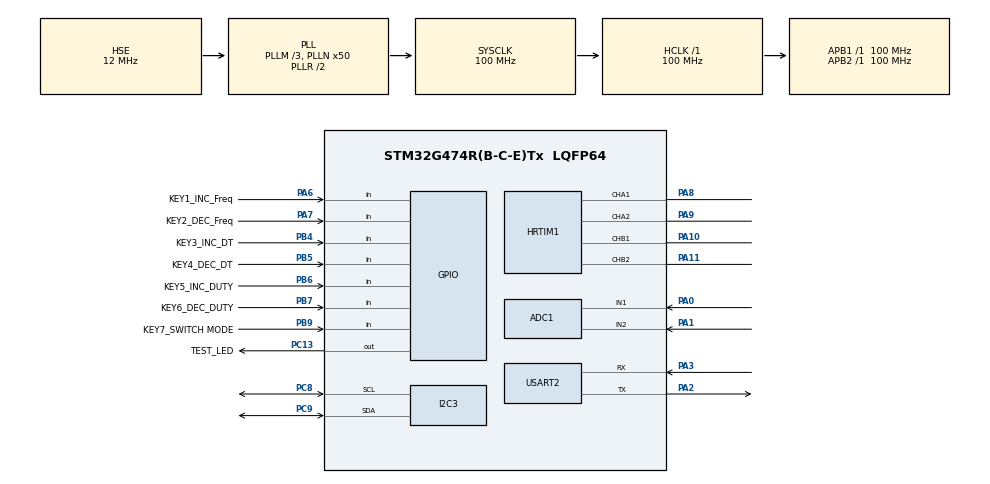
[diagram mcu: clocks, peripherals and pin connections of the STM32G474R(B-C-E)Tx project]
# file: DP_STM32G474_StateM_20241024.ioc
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ADC1.Channel-1\#ChannelRegularConversion=ADC_CHANNEL_1
ADC1.NbrOfConversionFlag=1
ADC1.OffsetNumber-1\#ChannelRegularConversion=ADC_OFFSET_NONE
ADC1.Rank-1\#ChannelRegularConversion=1
ADC1.SamplingTime-1\#ChannelRegularConversion=ADC_SAMPLETIME_2CYCLES_5
ADC1.master=1
Dma.ADC1.2.Direction=DMA_PERIPH_TO_MEMORY
Dma.ADC1.2.EventEnable=DISABLE
Dma.ADC1.2.Instance=DMA1_Channel1
Dma.ADC1.2.MemDataAlignment=DMA_MDATAALIGN_HALFWORD
Dma.ADC1.2.MemInc=DMA_MINC_ENABLE
Dma.ADC1.2.Mode=DMA_NORMAL
Dma.ADC1.2.PeriphDataAlignment=DMA_PDATAALIGN_HALFWORD
Dma.ADC1.2.PeriphInc=DMA_PINC_DISABLE
Dma.ADC1.2.Polarity=HAL_DMAMUX_REQ_GEN_RISING
Dma.ADC1.2.Priority=DMA_PRIORITY_LOW
Dma.ADC1.2.RequestNumber=1
Dma.ADC1.2.SignalID=NONE
Dma.ADC1.2.SyncEnable=DISABLE
Dma.ADC1.2.SyncPolarity=HAL_DMAMUX_SYNC_NO_EVENT
Dma.ADC1.2.SyncRequestNumber=1
Dma.ADC1.2.SyncSignalID=NONE
Dma.I2C3_TX.1.Direction=DMA_MEMORY_TO_PERIPH
Dma.I2C3_TX.1.EventEnable=DISABLE
Dma.I2C3_TX.1.Instance=DMA1_Channel2
Dma.I2C3_TX.1.MemDataAlignment=DMA_MDATAALIGN_BYTE
Dma.I2C3_TX.1.MemInc=DMA_MINC_ENABLE
Dma.I2C3_TX.1.Mode=DMA_NORMAL
Dma.I2C3_TX.1.PeriphDataAlignment=DMA_PDATAALIGN_BYTE
Dma.I2C3_TX.1.PeriphInc=DMA_PINC_DISABLE
Dma.I2C3_TX.1.Polarity=HAL_DMAMUX_REQ_GEN_RISING
Dma.I2C3_TX.1.Priority=DMA_PRIORITY_LOW
Dma.I2C3_TX.1.RequestNumber=1
Dma.I2C3_TX.1.SignalID=NONE
Dma.I2C3_TX.1.SyncEnable=DISABLE
Dma.I2C3_TX.1.SyncPolarity=HAL_DMAMUX_SYNC_NO_EVENT
Dma.I2C3_TX.1.SyncRequestNumber=1
Dma.I2C3_TX.1.SyncSignalID=NONE
Dma.Request0=USART2_TX
Dma.Request1=I2C3_TX
Dma.Request2=ADC1
Dma.USART2_TX.0.Direction=DMA_MEMORY_TO_PERIPH
Dma.USART2_TX.0.EventEnable=DISABLE
Dma.USART2_TX.0.Instance=DMA1_Channel3
Dma.USART2_TX.0.MemDataAlignment=DMA_MDATAALIGN_BYTE
Dma.USART2_TX.0.MemInc=DMA_MINC_ENABLE
Dma.USART2_TX.0.Mode=DMA_NORMAL
Dma.USART2_TX.0.PeriphDataAlignment=DMA_PDATAALIGN_BYTE
Dma.USART2_TX.0.PeriphInc=DMA_PINC_DISABLE
Dma.USART2_TX.0.Polarity=HAL_DMAMUX_REQ_GEN_RISING
Dma.USART2_TX.0.Priority=DMA_PRIORITY_LOW
Dma.USART2_TX.0.RequestNumber=1
Dma.USART2_TX.0.SignalID=NONE
Dma.USART2_TX.0.SyncEnable=DISABLE
Dma.USART2_TX.0.SyncPolarity=HAL_DMAMUX_SYNC_NO_EVENT
Dma.USART2_TX.0.SyncRequestNumber=1
Dma.USART2_TX.0.SyncSignalID=NONE
HRTIM1.CompareUnit1-Output_TA1TA2=HRTIM_COMPAREUNIT_1
HRTIM1.CompareUnit1-Output_TB1TB2=HRTIM_COMPAREUNIT_1
HRTIM1.CompareUnit2-Output_TA1TA2=HRTIM_COMPAREUNIT_2
HRTIM1.CompareUnit2-Output_TB1TB2=HRTIM_COMPAREUNIT_2
HRTIM1.CompareUnit3-Output_TA1TA2=HRTIM_COMPAREUNIT_3
HRTIM1.CompareUnit3-Output_TB1TB2=HRTIM_COMPAREUNIT_3
HRTIM1.CompareValue1-Output_TA1TA2=0
HRTIM1.CompareValue1-Output_TB1TB2=0
HRTIM1.CompareValue2-Output_TA1TA2=16000/2
HRTIM1.CompareValue2-Output_TB1TB2=16000/2
HRTIM1.CompareValue3-Output_TA1TA2=0
HRTIM1.CompareValue3-Output_TB1TB2=0
HRTIM1.Configuration_TA=Waveform
HRTIM1.NumberResetSource1-Output_TA1TA2=1
HRTIM1.NumberResetSource1-Output_TB1TB2=1
HRTIM1.NumberResetSource2_TA=1
HRTIM1.NumberResetSource2_TB=1
HRTIM1.NumberResetTrigger-Output_TA1TA2=1
HRTIM1.NumberResetTrigger-Output_TB1TB2=1
HRTIM1.NumberSetSource1-Output_TA1TA2=1
HRTIM1.NumberSetSource1-Output_TB1TB2=1
HRTIM1.NumberSetSource2_TA=1
HRTIM1.NumberSetSource2_TB=1
HRTIM1.NumberUpdateTrigger-Output_TA1TA2=1
HRTIM1.NumberUpdateTrigger-Output_TB1TB2=1
HRTIM1.Periode_TA=16000
HRTIM1.Periode_TB=16000
HRTIM1.Polarity1-Output_TA1TA2=HRTIM_OUTPUTPOLARITY_LOW
HRTIM1.Polarity2-Output_TA1TA2=HRTIM_OUTPUTPOLARITY_LOW
HRTIM1.PrescalerRatio_TA=HRTIM_PRESCALERRATIO_MUL16
HRTIM1.PrescalerRatio_TB=HRTIM_PRESCALERRATIO_MUL16
HRTIM1.RepetitionCounter-Output_TA1TA2=0
HRTIM1.RepetitionCounter-Output_TB1TB2=0
HRTIM1.ResetOutput1_Source1-Output_TA1TA2=HRTIM_OUTPUTRESET_TIMPER
HRTIM1.ResetOutput1_Source1-Output_TB1TB2=HRTIM_OUTPUTRESET_TIMCMP1
HRTIM1.ResetOutput2_Source1-Output_TA1TA2=HRTIM_OUTPUTRESET_TIMPER
HRTIM1.ResetOutput2_Source1-Output_TB1TB2=HRTIM_OUTPUTRESET_TIMCMP1
HRTIM1.ResetTrigger1-Output_TA1TA2=HRTIM_TIMRESETTRIGGER_UPDATE
HRTIM1.ResetTrigger1-Output_TB1TB2=HRTIM_TIMRESETTRIGGER_UPDATE
HRTIM1.ResetUpdate-Output_TA1TA2=HRTIM_TIMUPDATEONRESET_ENABLED
HRTIM1.ResetUpdate-Output_TB1TB2=HRTIM_TIMUPDATEONRESET_ENABLED
HRTIM1.SetOutput1_Source1-Output_TA1TA2=HRTIM_OUTPUTSET_TIMCMP2
HRTIM1.SetOutput1_Source1-Output_TB1TB2=HRTIM_OUTPUTSET_TIMCMP2
HRTIM1.SetOutput2_Source1-Output_TA1TA2=HRTIM_OUTPUTSET_TIMCMP2
HRTIM1.SetOutput2_Source1-Output_TB1TB2=HRTIM_OUTPUTSET_TIMCMP2
HRTIM1.UpdateTrigger1-Output_TA1TA2=HRTIM_TIMUPDATETRIGGER_TIMER_A
HRTIM1.UpdateTrigger1-Output_TB1TB2=HRTIM_TIMUPDATETRIGGER_TIMER_A
I2C3.Timing=0x20B182BE
Mcu.Family=STM32G4
Mcu.Name=STM32G474R(B-C-E)Tx
Mcu.Package=LQFP64
NVIC.ADC1_2_IRQn=true\:0\:0\:false\:false\:true\:true\:true\:true
NVIC.DMA1_Channel1_IRQn=true\:0\:0\:false\:false\:true\:false\:true\:true
NVIC.DMA1_Channel2_IRQn=true\:0\:0\:false\:false\:true\:false\:true\:true
NVIC.DMA1_Channel3_IRQn=true\:0\:0\:false\:false\:true\:false\:true\:true
NVIC.PriorityGroup=NVIC_PRIORITYGROUP_4
NVIC.TIM2_IRQn=true\:0\:0\:false\:false\:true\:true\:true\:true
NVIC.USART2_IRQn=true\:0\:0\:false\:false\:true\:true\:true\:true
PA0.Mode=IN1-Single-Ended
PA0.Signal=ADC1_IN1
PA1.Mode=IN1-Differential
PA1.Signal=ADC1_IN2
PA10.Mode=Output_TB1TB2
PA10.Signal=HRTIM1_CHB1
PA11.Mode=Output_TB1TB2
PA11.Signal=HRTIM1_CHB2
PA13.Mode=Serial_Wire
PA13.Signal=SYS_JTMS-SWDIO
PA14.Mode=Serial_Wire
PA14.Signal=SYS_JTCK-SWCLK
PA2.Mode=Asynchronous
PA2.Signal=USART2_TX
PA3.Mode=Asynchronous
PA3.Signal=USART2_RX
PA6.GPIO_Label=KEY1_INC_Freq
PA6.GPIO_PuPd=GPIO_PULLUP
PA6.Signal=GPIO_Input
PA7.GPIO_Label=KEY2_DEC_Freq
PA7.GPIO_PuPd=GPIO_PULLUP
PA7.Signal=GPIO_Input
PA8.Mode=Output_TA1TA2
PA8.Signal=HRTIM1_CHA1
PA9.Mode=Output_TA1TA2
PA9.Signal=HRTIM1_CHA2
PB4.GPIO_Label=KEY3_INC_DT
PB4.GPIO_PuPd=GPIO_PULLUP
PB4.Signal=GPIO_Input
PB5.GPIO_Label=KEY4_DEC_DT
PB5.GPIO_PuPd=GPIO_PULLUP
PB5.Signal=GPIO_Input
PB6.GPIO_Label=KEY5_INC_DUTY
PB6.GPIO_PuPd=GPIO_PULLUP
PB6.Signal=GPIO_Input
PB7.GPIO_Label=KEY6_DEC_DUTY
PB7.GPIO_PuPd=GPIO_PULLUP
PB7.Signal=GPIO_Input
PB9.GPIO_Label=KEY7_SWITCH MODE
PB9.GPIO_PuPd=GPIO_PULLUP
PB9.Signal=GPIO_Input
PC13.GPIO_Label=TEST_LED
PC13.PinState=GPIO_PIN_SET
PC13.Signal=GPIO_Output
PC14-OSC32_IN.Mode=LSE-External-Oscillator
PC14-OSC32_IN.Signal=RCC_OSC32_IN
PC15-OSC32_OUT.Mode=LSE-External-Oscillator
PC15-OSC32_OUT.Signal=RCC_OSC32_OUT
PC8.GPIO_Pu=GPIO_PULLUP
PC8.Mode=I2C
PC8.Signal=I2C3_SCL
PC9.GPIO_Pu=GPIO_PULLUP
PC9.Mode=I2C
PC9.Signal=I2C3_SDA
PF0-OSC_IN.Mode=HSE-External-Oscillator
PF0-OSC_IN.Signal=RCC_OSC_IN
PF1-OSC_OUT.Mode=HSE-External-Oscillator
PF1-OSC_OUT.Signal=RCC_OSC_OUT
ProjectManager.HeapSize=0x200
ProjectManager.StackSize=0x400
ProjectManager.TargetToolchain=MDK-ARM V5.27
RCC.ADC12Freq_Value=100000000
RCC.ADC345Freq_Value=100000000
RCC.AHBFreq_Value=100000000
RCC.APB1Freq_Value=100000000
RCC.APB1TimFreq_Value=100000000
RCC.APB2Freq_Value=100000000
RCC.APB2TimFreq_Value=100000000
RCC.CortexFreq_Value=100000000
RCC.EXTERNAL_CLOCK_VALUE=12288000
RCC.HCLKFreq_Value=100000000
RCC.HSE_VALUE=12000000
RCC.HSI48_VALUE=48000000
RCC.HSI_VALUE=16000000
RCC.PLLM=RCC_PLLM_DIV3
RCC.PLLN=50
RCC.PLLSourceVirtual=RCC_PLLSOURCE_HSE
RCC.SYSCLKFreq_VALUE=100000000
RCC.SYSCLKSource=RCC_SYSCLKSOURCE_PLLCLK
RCC.USBFreq_Value=100000000
RCC.VCOOutputFreq_Value=200000000
TIM2.AutoReloadPreload=TIM_AUTORELOAD_PRELOAD_ENABLE
TIM2.ClockDivision=TIM_CLOCKDIVISION_DIV4
TIM2.PeriodNoDither=500-1
TIM2.Prescaler=35000-1
USART2.VirtualMode-Asynchronous=VM_ASYNC
VP_SYS_VS_DBSignals.Mode=DisableDeadBatterySignals
VP_TIM2_VS_ClockSourceINT.Mode=Internal
board=custom

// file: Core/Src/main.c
/* USER CODE BEGIN Header */
/**
  ******************************************************************************
  * @file           : main.c
  * @brief          : Main program body
  ******************************************************************************
  * @attention
  *
  * Copyright (c) 2024 STMicroelectronics.
  * All rights reserved.
  *
  * This software is licensed under terms that can be found in the LICENSE file
  * in the root directory of this software component.
  * If no LICENSE file comes with this software, it is provided AS-IS.
  *
  ******************************************************************************
  */
/* USER CODE END Header */
#include "main.h"
#include "adc.h"
#include "dma.h"
#include "hrtim.h"
#include "i2c.h"
#include "tim.h"
#include "usart.h"
#include "gpio.h"

/* USER CODE BEGIN Includes */
#include "oled.h"
#include "function.h"
/* USER CODE END Includes */

void SystemClock_Config(void);

int main(void)
{

  /* MCU Configuration--------------------------------------------------------*/

  /* Reset of all peripherals, Initializes the Flash interface and the Systick. */
  HAL_Init();

  /* Configure the system clock */
  SystemClock_Config();

  /* Initialize all configured peripherals */
  MX_GPIO_Init();
  MX_DMA_Init();
  MX_HRTIM1_Init();
  MX_USART2_UART_Init();
  MX_I2C3_Init();
  MX_TIM2_Init();
  MX_ADC1_Init();
  /* USER CODE BEGIN 2 */
	OLED_Open_Mode_Init(); // Initialize OLED display

	HAL_TIM_Base_Start_IT(&htim2); // Start timer 3 at 200Hz

	HAL_ADC_Start_DMA(&hadc1, (uint32_t*)ADC1_RESULT, 4); // Start ADC1 sampling, DMA transfer for sampling input/output voltage and current
	HAL_ADC_Start(&hadc1); // Start ADC2 sampling, sampling the sliding potentiometer voltage

	// 啟動四路 PWM 輸出（TA1、TA2、TB1、TB2）
	HAL_HRTIM_WaveformOutputStart(&hhrtim1, HRTIM_OUTPUT_TA1 | HRTIM_OUTPUT_TA2 | HRTIM_OUTPUT_TB1 | HRTIM_OUTPUT_TB2); // Enable all PWM outputs

	// 啟動計時器 A 和 B
	HAL_HRTIM_WaveformCounterStart(&hhrtim1, HRTIM_TIMERID_TIMER_A | HRTIM_TIMERID_TIMER_B); // Start both PWM timers

	// 啟用計時器 A 的中斷
	__HAL_HRTIM_TIMER_ENABLE_IT(&hhrtim1, HRTIM_TIMERINDEX_TIMER_A, HRTIM_TIM_IT_REP); // Enable interrupt for timer A

  /* USER CODE END 2 */

  /* Infinite loop */
  while (1)
  {

    /* USER CODE BEGIN 3 */
		if(OLEDShowCnt>60)//300m????
		{
			OLEDShowCnt=0;
			//OLEDShow();
		}
  }
  /* USER CODE END 3 */
}

void SystemClock_Config(void)
{
  RCC_OscInitTypeDef RCC_OscInitStruct = {0};
  RCC_ClkInitTypeDef RCC_ClkInitStruct = {0};

  /** Configure the main internal regulator output voltage
  */
  HAL_PWREx_ControlVoltageScaling(PWR_REGULATOR_VOLTAGE_SCALE1);

  /** Initializes the RCC Oscillators according to the specified parameters
  * in the RCC_OscInitTypeDef structure.
  */
  RCC_OscInitStruct.OscillatorType = RCC_OSCILLATORTYPE_HSE;
  RCC_OscInitStruct.HSEState = RCC_HSE_ON;
  RCC_OscInitStruct.PLL.PLLState = RCC_PLL_ON;
  RCC_OscInitStruct.PLL.PLLSource = RCC_PLLSOURCE_HSE;
  RCC_OscInitStruct.PLL.PLLM = RCC_PLLM_DIV3;
  RCC_OscInitStruct.PLL.PLLN = 50;
  RCC_OscInitStruct.PLL.PLLP = RCC_PLLP_DIV2;
  RCC_OscInitStruct.PLL.PLLQ = RCC_PLLQ_DIV2;
  RCC_OscInitStruct.PLL.PLLR = RCC_PLLR_DIV2;
  if (HAL_RCC_OscConfig(&RCC_OscInitStruct) != HAL_OK)
  {
    Error_Handler();
  }

  /** Initializes the CPU, AHB and APB buses clocks
  */
  RCC_ClkInitStruct.ClockType = RCC_CLOCKTYPE_HCLK|RCC_CLOCKTYPE_SYSCLK
                              |RCC_CLOCKTYPE_PCLK1|RCC_CLOCKTYPE_PCLK2;
  RCC_ClkInitStruct.SYSCLKSource = RCC_SYSCLKSOURCE_PLLCLK;
  RCC_ClkInitStruct.AHBCLKDivider = RCC_SYSCLK_DIV1;
  RCC_ClkInitStruct.APB1CLKDivider = RCC_HCLK_DIV1;
  RCC_ClkInitStruct.APB2CLKDivider = RCC_HCLK_DIV1;

  if (HAL_RCC_ClockConfig(&RCC_ClkInitStruct, FLASH_LATENCY_3) != HAL_OK)
  {
    Error_Handler();
  }
}

void Error_Handler(void)
{
  __disable_irq();
  while (1)
  {
  }
}
